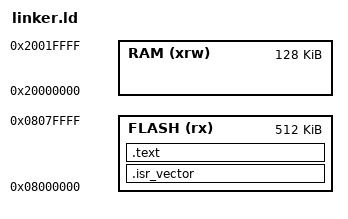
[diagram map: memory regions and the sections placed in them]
MEMORY
{
    FLASH (rx) : ORIGIN = 0x08000000, LENGTH = 512K
    RAM  (xrw) : ORIGIN = 0x20000000, LENGTH = 128K
}

SECTIONS
{
    .isr_vector :
    {
        . = ALIGN(4);
        KEEP(*(.isr_vector))
        . = ALIGN(4);
    } > FLASH

    .text :
    {
        . = ALIGN(4);
        *(.text)
        *(.text*)
        . = ALIGN(4);
    } > FLASH
}
